# M369 register map
File version: 0.1
CPU: 
Registers are 32-bit, read-write, reset 0x0 unless marked. A register's access mark holds for its fields unless they carry their own. Offsets are from the block's base; [hi:lo] are bit positions; {n}, {i} and the like mark numbered series; 'fields as' and 'values as' point back to an identical list.

## EM — UDC2 AHB Bridge
Base 0x4000A000
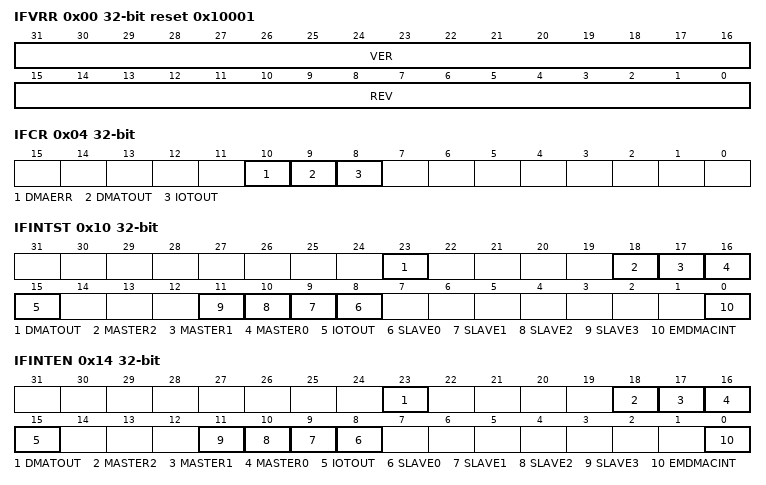
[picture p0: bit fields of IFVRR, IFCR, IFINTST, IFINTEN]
0x00 IFVRR ro reset 0x10001 — ADiC Version_Revision Register
  [31:16] VER, [15:0] REV
0x04 IFCR — ADiC MODE Setting Register
  [10] DMAERR, [9] DMATOUT, [8] IOTOUT
0x10 IFINTST — ADiC Interrupt Status Register
  [23] DMATOUT, [18] MASTER2, [17] MASTER1, [16] MASTER0, [15] IOTOUT, [n+8] SLAVE{n} (n=0..3), [0] EMDMACINT
0x14 IFINTEN — ADiC Interrupt Enable Register
  fields as IFINTST
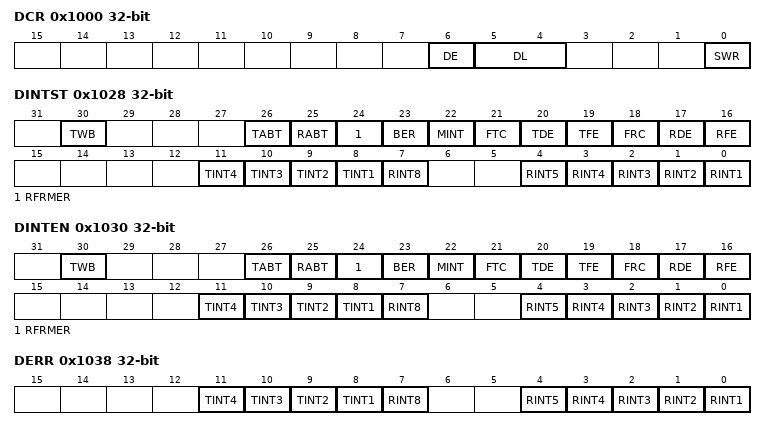
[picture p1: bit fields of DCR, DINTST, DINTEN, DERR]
0x1000 DCR — EMDMAC Movement Control Register
  [6] DE, [5:4] DL, [0] SWR
0x1008 DTEN — Transmission Instructions Register
  [0] TRNS
0x1010 DREN — Reception instructions Register
  [0] RCV
0x1018 DTDPR — Transmission Dscripter top address setting Register
  [31:0] TDPA
0x1020 DRDPR — Reception Dscripter top address setting Register
  [31:0] RDPA
0x1028 DINTST — EMSMAC Interrupt Status Indication Register
  [30] TWB, [26] TABT, [25] RABT, [24] RFRMER, [23] BER, [22] MINT, [21] FTC, [20] TDE, [19] TFE, [18] FRC, [17] RDE, [16] RFE, [n+7] TINT{n} (n=1..4), [7] RINT8, [n-1] RINT{n} (n=1..5)
0x1030 DINTEN — EMDMAC Interrupt mask setting Register
  fields as DINTST
0x1038 DERR — Err Mask Setting Register
  [n+7] TINT{n} (n=1..4), [7] RINT8, [n-1] RINT{n} (n=1..5)
0x1040 DMFCR — Disposal Frame Count Register
  [15:0] MIS
0x1048 DTFTR — Transmission FIFO thresholding Register
  [10:0] TFTH
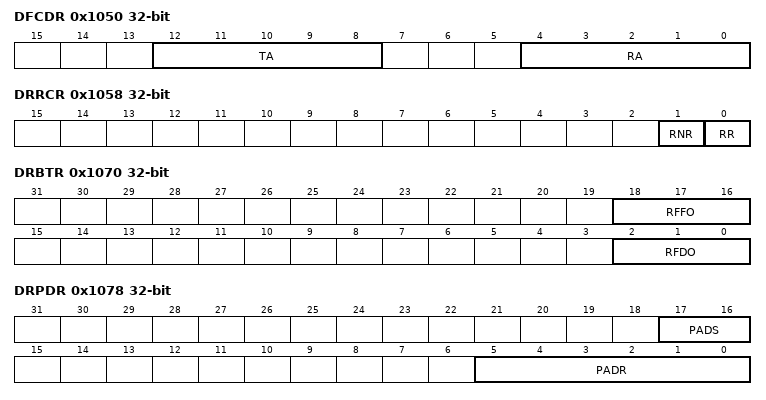
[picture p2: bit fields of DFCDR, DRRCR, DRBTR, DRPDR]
0x1050 DFCDR — Outside FIFO Capacity Setting Register
  [12:8] TA, [4:0] RA
0x1058 DRRCR — Reception Start Reset Setting Register
  [1] RNR, [0] RR
0x1060 DEADR — DMA Error Address Register
  [31:0] ERRADR
0x1064 DTUFR — Transmission FIFO Underflow Count Register
  [15:0] UNDER
0x1068 DROFR — Reception FIFO Underflow Count Register
  [15:0] OVER
0x1070 DRBTR — Transmission FIFO Busy Transmission Thresholding Register
  [18:16] RFFO, [2:0] RFDO
0x1078 DRPDR — Reception Data Padding setting Register
  [17:16] PADS, [5:0] PADR
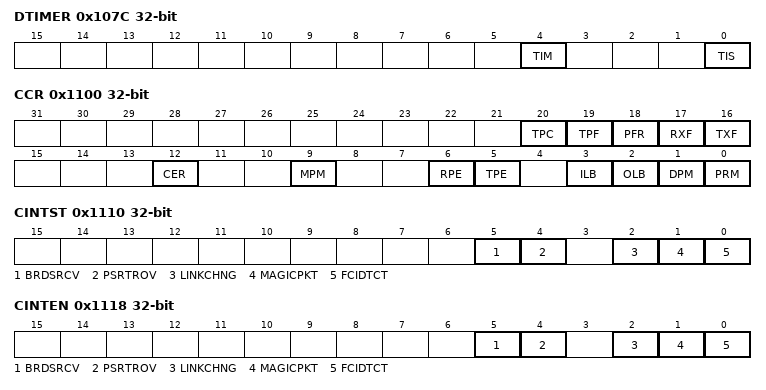
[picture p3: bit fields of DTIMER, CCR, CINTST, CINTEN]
0x107C DTIMER — Transmission Interrupt Mode Setting Register
  [4] TIM, [0] TIS
0x10C8 DRBAR ro — Reception Buffer Light Address For debugging Register
  [31:0] RBWA
0x10CC DRDAR ro — Reception Dscripter Read Address For Debugging Register
  [31:0] RDRA
0x10D4 DTBAR ro — Transmission Read Address For Debugging Register
  [31:0] TBRA
0x10D8 DTDAR ro — Transmission Dscripter Read Address For Debugging Register
  [31:0] TDRA
0x1100 CCR — Ether FeLic Active Mode Register
  [20] TPC, [19] TPF, [18] PFR, [17] RXF, [16] TXF, [12] CER, [9] MPM, [6] RPE, [5] TPE, [3] ILB, [2] OLB, [1] DPM, [0] PRM
0x1108 CRFLR — Long Frame Length Check Level Setting Register
  [11:0] FLEN_ULMT
0x1110 CINTST — Status indication Register
  [5] BRDSRCV, [4] PSRTROV, [2] LINKCHNG, [1] MAGICPKT, [0] FCIDTCT
0x1118 CINTEN — Interrupt mask setting Register
  [5] BRDSRCV, [4] PSRTROV, [2] LINKCHNG, [1] MAGICPKT, [0] FCIDTCT
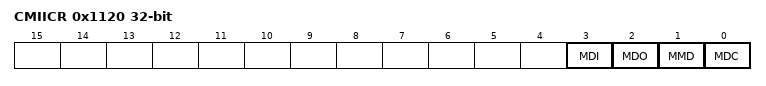
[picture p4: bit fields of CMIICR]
0x1120 CMIICR (reset mask 0xFFFFFFF7) — MII Control Register
  [3] MDI, [2] MDO, [1] MMD, [0] MDC
0x1128 CPHYST ro (reset mask 0xFFFFFFFE) — Status Signal Register
  [0] LINK
0x1150 CICR reset 0x14 — IPG Counter Setting Register
  [4:0] IPG
0x1154 CAPR — Auto Pause Parameter Setting Register
  [15:0] APAUSE
0x1158 CMPR — Manual Pause Parameter setting Register
  [15:0] MPAUSE wo
0x1160 CRPCR ro — Reception PAUSE Frame Counter Register
  [7:0] RPAUSE
0x1164 CPULR — PAUSE Frame Retransmission Number Of Times Setting Register
  [15:0] TXPAUSE
0x1168 CPCR ro — PAUSE Frame Retransmission Number Of Times Counter Register
  [15:0] TPAUSE
0x116C CBRR — Broadcast Frame Reception Number Of Times Setting Register
  [15:0] BCF
0x11C0 CMAHR — Mac Address Register (High Rank)
  [31:0] MACADRH
0x11C8 CMALR — Mac Address Register (Low Rank)
  [31:0] MACADRL
0x11D0 CTRER — TINT1 Cunter Register
  [31:0] TINT1CNT
0x11D4 CTCDR — TINT2 Cunter Register
  [31:0] TINT2CNT
0x11D8 CTCLR — TINT3 Cunter Register
  [31:0] TINT3CNT
0x11DC CTNDR — TINT4 Cunter Register
  [31:0] TINT4CNT
0x11E4 CRCER — RINT1 Cunter Register
  [31:0] RINT1CNT
0x11E8 CRFER — RINT2 Cunter Register
  [31:0] RINT2CNT
0x11EC CRLSR — RINT3 Cunter Register
  [31:0] RINT3CNT
0x11F0 CRLOR — RINT4 Cunter Register
  [31:0] RINT4CNT
0x11F4 CRRFR — RINT5 Cunter Register
  [31:0] RINT5CNT
0x11F8 CRMFR — RINT8 Cunter Register
  [31:0] RINT8CNT
